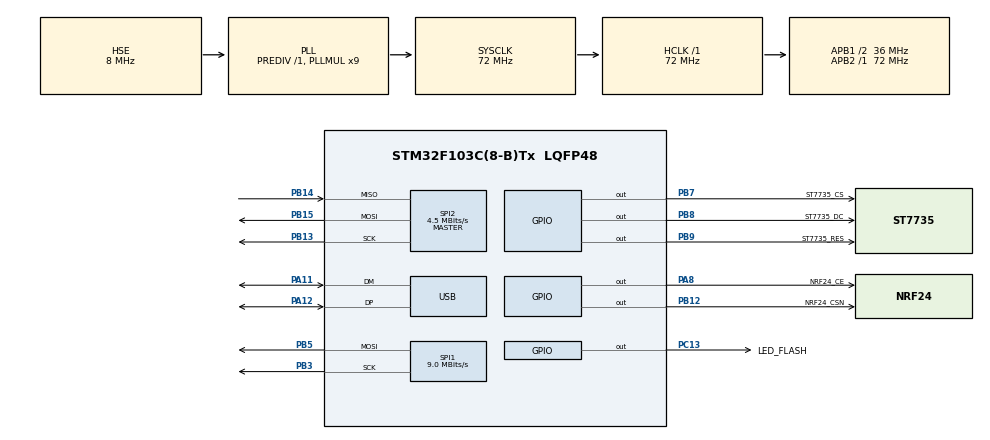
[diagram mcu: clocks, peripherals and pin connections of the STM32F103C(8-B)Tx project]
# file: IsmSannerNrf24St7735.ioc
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Mcu.Family=STM32F1
Mcu.Name=STM32F103C(8-B)Tx
Mcu.Package=LQFP48
NVIC.PriorityGroup=NVIC_PRIORITYGROUP_4
NVIC.USB_LP_CAN1_RX0_IRQn=true\:0\:0\:false\:false\:true\:false\:true
PA11.Mode=Device
PA11.Signal=USB_DM
PA12.Mode=Device
PA12.Signal=USB_DP
PA13.Mode=Serial_Wire
PA13.Signal=SYS_JTMS-SWDIO
PA14.Mode=Serial_Wire
PA14.Signal=SYS_JTCK-SWCLK
PA8.GPIO_Label=NRF24_CE
PA8.GPIO_ModeDefaultOutputPP=GPIO_MODE_OUTPUT_PP
PA8.GPIO_PuPd=GPIO_NOPULL
PA8.GPIO_Speed=GPIO_SPEED_FREQ_HIGH
PA8.PinState=GPIO_PIN_SET
PA8.Signal=GPIO_Output
PB12.GPIO_Label=NRF24_CSN
PB12.GPIO_Speed=GPIO_SPEED_FREQ_HIGH
PB12.PinState=GPIO_PIN_SET
PB12.Signal=GPIO_Output
PB13.Mode=Full_Duplex_Master
PB13.Signal=SPI2_SCK
PB14.Mode=Full_Duplex_Master
PB14.Signal=SPI2_MISO
PB15.Mode=Full_Duplex_Master
PB15.Signal=SPI2_MOSI
PB3.Mode=TX_Only_Simplex_Unidirect_Master
PB3.Signal=SPI1_SCK
PB5.Mode=TX_Only_Simplex_Unidirect_Master
PB5.Signal=SPI1_MOSI
PB7.GPIO_Label=ST7735_CS
PB7.Signal=GPIO_Output
PB8.GPIO_Label=ST7735_DC
PB8.Signal=GPIO_Output
PB9.GPIO_Label=ST7735_RES
PB9.Signal=GPIO_Output
PC13-TAMPER-RTC.GPIO_Label=LED_FLASH
PC13-TAMPER-RTC.Signal=GPIO_Output
PD0-OSC_IN.Mode=HSE-External-Oscillator
PD0-OSC_IN.Signal=RCC_OSC_IN
PD1-OSC_OUT.Mode=HSE-External-Oscillator
PD1-OSC_OUT.Signal=RCC_OSC_OUT
ProjectManager.HeapSize=0x200
ProjectManager.StackSize=0x400
ProjectManager.TargetToolchain=STM32CubeIDE
RCC.AHBFreq_Value=72000000
RCC.APB1CLKDivider=RCC_HCLK_DIV2
RCC.APB1Freq_Value=36000000
RCC.APB1TimFreq_Value=72000000
RCC.APB2Freq_Value=72000000
RCC.APB2TimFreq_Value=72000000
RCC.HCLKFreq_Value=72000000
RCC.PLLMUL=RCC_PLL_MUL9
RCC.SYSCLKFreq_VALUE=72000000
RCC.SYSCLKSource=RCC_SYSCLKSOURCE_PLLCLK
RCC.USBFreq_Value=48000000
RCC.USBPrescaler=RCC_USBCLKSOURCE_PLL_DIV1_5
SPI1.BaudRatePrescaler=SPI_BAUDRATEPRESCALER_8
SPI1.CalculateBaudRate=9.0 MBits/s
SPI1.Direction=SPI_DIRECTION_2LINES
SPI1.Mode=SPI_MODE_MASTER
SPI1.VirtualType=VM_MASTER
SPI2.BaudRatePrescaler=SPI_BAUDRATEPRESCALER_8
SPI2.CalculateBaudRate=4.5 MBits/s
SPI2.Direction=SPI_DIRECTION_2LINES
SPI2.Mode=SPI_MODE_MASTER
SPI2.VirtualType=VM_MASTER
USB_DEVICE.CLASS_NAME_FS=CDC
USB_DEVICE.VirtualMode=Cdc
USB_DEVICE.VirtualModeFS=Cdc_FS
VP_USB_DEVICE_VS_USB_DEVICE_CDC_FS.Mode=CDC_FS
board=custom

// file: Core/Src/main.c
/* USER CODE BEGIN Header */
/**
  ******************************************************************************
  * @file           : main.c
  * @brief          : Main program body
  ******************************************************************************
  * @attention
  *
  * <h2><center>&copy; Copyright (c) 2020 STMicroelectronics.
  * All rights reserved.</center></h2>
  *
  * This software component is licensed by ST under BSD 3-Clause license,
  * the "License"; You may not use this file except in compliance with the
  * License. You may obtain a copy of the License at:
  *                        opensource.org/licenses/BSD-3-Clause
  *
  ******************************************************************************
  */
/* USER CODE END Header */
#include "main.h"
#include "usb_device.h"

/* USER CODE BEGIN Includes */
#include "Scanner.h"
/* USER CODE END Includes */

SPI_HandleTypeDef hspi1;
SPI_HandleTypeDef hspi2;

void SystemClock_Config(void);
static void MX_GPIO_Init(void);
static void MX_SPI1_Init(void);
static void MX_SPI2_Init(void);

int main(void)
{

  /* MCU Configuration--------------------------------------------------------*/

  /* Reset of all peripherals, Initializes the Flash interface and the Systick. */
  HAL_Init();

  /* Configure the system clock */
  SystemClock_Config();

  /* Initialize all configured peripherals */
  MX_GPIO_Init();
  MX_USB_DEVICE_Init();
  MX_SPI1_Init();
  MX_SPI2_Init();
  /* USER CODE BEGIN 2 */
  void (*fcall)(void);
  fcall=p_setupScann;
  fcall();

  fcall=p_loopScann;

  /* USER CODE END 2 */

  /* Infinite loop */
  while (1)
  {

    /* USER CODE BEGIN 3 */

	  fcall();

  }
  /* USER CODE END 3 */
}

void SystemClock_Config(void)
{
  RCC_OscInitTypeDef RCC_OscInitStruct = {0};
  RCC_ClkInitTypeDef RCC_ClkInitStruct = {0};
  RCC_PeriphCLKInitTypeDef PeriphClkInit = {0};

  /** Initializes the RCC Oscillators according to the specified parameters
  * in the RCC_OscInitTypeDef structure.
  */
  RCC_OscInitStruct.OscillatorType = RCC_OSCILLATORTYPE_HSE;
  RCC_OscInitStruct.HSEState = RCC_HSE_ON;
  RCC_OscInitStruct.HSEPredivValue = RCC_HSE_PREDIV_DIV1;
  RCC_OscInitStruct.HSIState = RCC_HSI_ON;
  RCC_OscInitStruct.PLL.PLLState = RCC_PLL_ON;
  RCC_OscInitStruct.PLL.PLLSource = RCC_PLLSOURCE_HSE;
  RCC_OscInitStruct.PLL.PLLMUL = RCC_PLL_MUL9;
  if (HAL_RCC_OscConfig(&RCC_OscInitStruct) != HAL_OK)
  {
    Error_Handler();
  }
  /** Initializes the CPU, AHB and APB buses clocks
  */
  RCC_ClkInitStruct.ClockType = RCC_CLOCKTYPE_HCLK|RCC_CLOCKTYPE_SYSCLK
                              |RCC_CLOCKTYPE_PCLK1|RCC_CLOCKTYPE_PCLK2;
  RCC_ClkInitStruct.SYSCLKSource = RCC_SYSCLKSOURCE_PLLCLK;
  RCC_ClkInitStruct.AHBCLKDivider = RCC_SYSCLK_DIV1;
  RCC_ClkInitStruct.APB1CLKDivider = RCC_HCLK_DIV2;
  RCC_ClkInitStruct.APB2CLKDivider = RCC_HCLK_DIV1;

  if (HAL_RCC_ClockConfig(&RCC_ClkInitStruct, FLASH_LATENCY_2) != HAL_OK)
  {
    Error_Handler();
  }
  PeriphClkInit.PeriphClockSelection = RCC_PERIPHCLK_USB;
  PeriphClkInit.UsbClockSelection = RCC_USBCLKSOURCE_PLL_DIV1_5;
  if (HAL_RCCEx_PeriphCLKConfig(&PeriphClkInit) != HAL_OK)
  {
    Error_Handler();
  }
}

static void MX_SPI1_Init(void)
{

  /* SPI1 parameter configuration*/
  hspi1.Instance = SPI1;
  hspi1.Init.Mode = SPI_MODE_MASTER;
  hspi1.Init.Direction = SPI_DIRECTION_2LINES;
  hspi1.Init.DataSize = SPI_DATASIZE_8BIT;
  hspi1.Init.CLKPolarity = SPI_POLARITY_LOW;
  hspi1.Init.CLKPhase = SPI_PHASE_1EDGE;
  hspi1.Init.NSS = SPI_NSS_SOFT;
  hspi1.Init.BaudRatePrescaler = SPI_BAUDRATEPRESCALER_8;
  hspi1.Init.FirstBit = SPI_FIRSTBIT_MSB;
  hspi1.Init.TIMode = SPI_TIMODE_DISABLE;
  hspi1.Init.CRCCalculation = SPI_CRCCALCULATION_DISABLE;
  hspi1.Init.CRCPolynomial = 10;
  if (HAL_SPI_Init(&hspi1) != HAL_OK)
  {
    Error_Handler();
  }

}

static void MX_SPI2_Init(void)
{

  /* SPI2 parameter configuration*/
  hspi2.Instance = SPI2;
  hspi2.Init.Mode = SPI_MODE_MASTER;
  hspi2.Init.Direction = SPI_DIRECTION_2LINES;
  hspi2.Init.DataSize = SPI_DATASIZE_8BIT;
  hspi2.Init.CLKPolarity = SPI_POLARITY_LOW;
  hspi2.Init.CLKPhase = SPI_PHASE_1EDGE;
  hspi2.Init.NSS = SPI_NSS_SOFT;
  hspi2.Init.BaudRatePrescaler = SPI_BAUDRATEPRESCALER_8;
  hspi2.Init.FirstBit = SPI_FIRSTBIT_MSB;
  hspi2.Init.TIMode = SPI_TIMODE_DISABLE;
  hspi2.Init.CRCCalculation = SPI_CRCCALCULATION_DISABLE;
  hspi2.Init.CRCPolynomial = 10;
  if (HAL_SPI_Init(&hspi2) != HAL_OK)
  {
    Error_Handler();
  }

}

static void MX_GPIO_Init(void)
{
  GPIO_InitTypeDef GPIO_InitStruct = {0};

  /* GPIO Ports Clock Enable */
  __HAL_RCC_GPIOC_CLK_ENABLE();
  __HAL_RCC_GPIOD_CLK_ENABLE();
  __HAL_RCC_GPIOB_CLK_ENABLE();
  __HAL_RCC_GPIOA_CLK_ENABLE();

  /*Configure GPIO pin Output Level */
  HAL_GPIO_WritePin(LED_FLASH_GPIO_Port, LED_FLASH_Pin, GPIO_PIN_RESET);

  /*Configure GPIO pin Output Level */
  HAL_GPIO_WritePin(NRF24_CSN_GPIO_Port, NRF24_CSN_Pin, GPIO_PIN_SET);

  /*Configure GPIO pin Output Level */
  HAL_GPIO_WritePin(NRF24_CE_GPIO_Port, NRF24_CE_Pin, GPIO_PIN_SET);

  /*Configure GPIO pin Output Level */
  HAL_GPIO_WritePin(GPIOB, ST7735_CS_Pin|ST7735_DC_Pin|ST7735_RES_Pin, GPIO_PIN_RESET);

  /*Configure GPIO pin : LED_FLASH_Pin */
  GPIO_InitStruct.Pin = LED_FLASH_Pin;
  GPIO_InitStruct.Mode = GPIO_MODE_OUTPUT_PP;
  GPIO_InitStruct.Pull = GPIO_NOPULL;
  GPIO_InitStruct.Speed = GPIO_SPEED_FREQ_LOW;
  HAL_GPIO_Init(LED_FLASH_GPIO_Port, &GPIO_InitStruct);

  /*Configure GPIO pin : NRF24_CSN_Pin */
  GPIO_InitStruct.Pin = NRF24_CSN_Pin;
  GPIO_InitStruct.Mode = GPIO_MODE_OUTPUT_PP;
  GPIO_InitStruct.Pull = GPIO_NOPULL;
  GPIO_InitStruct.Speed = GPIO_SPEED_FREQ_HIGH;
  HAL_GPIO_Init(NRF24_CSN_GPIO_Port, &GPIO_InitStruct);

  /*Configure GPIO pin : NRF24_CE_Pin */
  GPIO_InitStruct.Pin = NRF24_CE_Pin;
  GPIO_InitStruct.Mode = GPIO_MODE_OUTPUT_PP;
  GPIO_InitStruct.Pull = GPIO_NOPULL;
  GPIO_InitStruct.Speed = GPIO_SPEED_FREQ_HIGH;
  HAL_GPIO_Init(NRF24_CE_GPIO_Port, &GPIO_InitStruct);

  /*Configure GPIO pins : ST7735_CS_Pin ST7735_DC_Pin ST7735_RES_Pin */
  GPIO_InitStruct.Pin = ST7735_CS_Pin|ST7735_DC_Pin|ST7735_RES_Pin;
  GPIO_InitStruct.Mode = GPIO_MODE_OUTPUT_PP;
  GPIO_InitStruct.Pull = GPIO_NOPULL;
  GPIO_InitStruct.Speed = GPIO_SPEED_FREQ_LOW;
  HAL_GPIO_Init(GPIOB, &GPIO_InitStruct);

}

void Error_Handler(void)
{
  __disable_irq();
  while (1)
  {
  }
}

/************************ (C) COPYRIGHT STMicroelectronics *****END OF FILE****/
